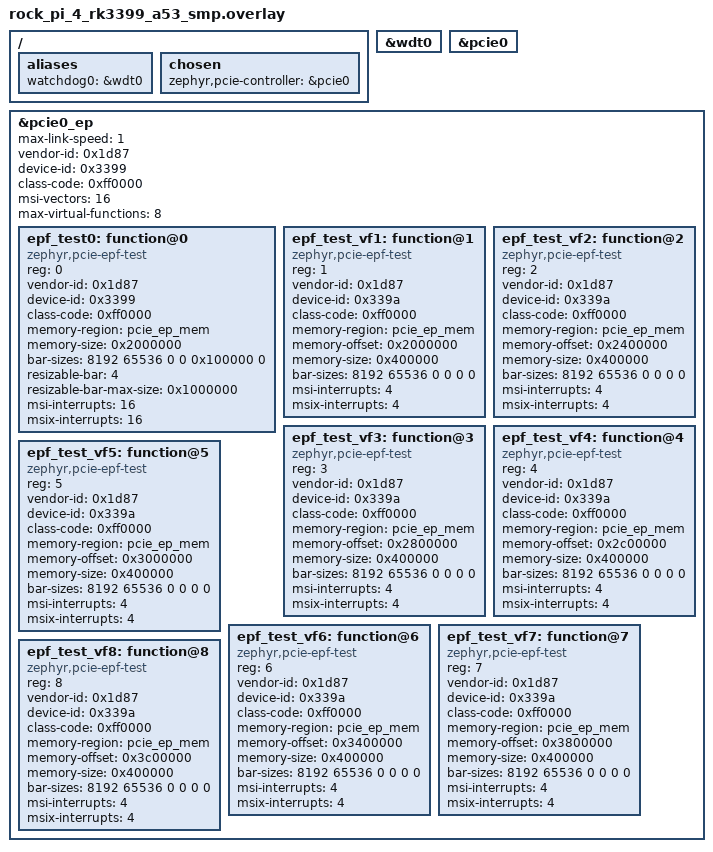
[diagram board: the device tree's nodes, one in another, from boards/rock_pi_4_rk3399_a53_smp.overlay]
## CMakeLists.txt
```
# SPDX-License-Identifier: Apache-2.0

cmake_minimum_required(VERSION 3.20.0)
find_package(Zephyr REQUIRED HINTS $ENV{ZEPHYR_BASE})
project(rk3399_pcie_shell)
target_sources_ifdef(CONFIG_SMP app PRIVATE src/ep_affinity.c)

target_sources(app PRIVATE src/main.c src/cpuinfo.c)
```

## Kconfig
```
# Copyright The Zephyr Project Contributors
# SPDX-License-Identifier: Apache-2.0

source "Kconfig.zephyr"

if SSH_SERVER

config PCIE_SHELL_SSH_USERNAME
	string "SSH user name (empty: any)"
	default "root"

config PCIE_SHELL_SSH_PASSWORD
	string "SSH password"
	default ""
	help
	  Stored in clear text in the image. Empty: the server is not
	  started.

config PCIE_SHELL_SSH_HOST_KEY_BITS
	int "RSA host key size"
	default 2048
	help
	  Generated on the first boot and kept in the settings file on the
	  eMMC FAT; without it, a new key (and fingerprint) on every boot.

endif
```

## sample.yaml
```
sample:
  name: RK3399 PCIe shell (root complex / endpoint)
tests:
  sample.boards.rockchip.rk3399.pcie_shell:
    platform_allow:
      - rock_pi_4/rk3399/a53
      - rock_pi_4/rk3399/a53/smp
      - rock_pi_4/rk3399/a53/hmp
    tags: pcie
    build_only: true
  sample.boards.rockchip.rk3399.pcie_shell.ssh:
    platform_allow:
      - rock_pi_4/rk3399/a53/smp
      - rock_pi_4/rk3399/a53/hmp
    tags: pcie
    build_only: true
    extra_args:
      - EXTRA_CONF_FILE=ssh.conf
      - CONFIG_PCIE_SHELL_SSH_PASSWORD="test"
```

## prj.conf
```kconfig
CONFIG_GPIO=y
CONFIG_LOG=y
CONFIG_SHELL=y
CONFIG_KERNEL_SHELL=y
CONFIG_DEVMEM_SHELL=y
CONFIG_REBOOT=y
CONFIG_SHELL_STACK_SIZE=8192

# root complex
CONFIG_PCIE=y
CONFIG_PCIE_CONTROLLER=y
# endpoint
CONFIG_PCIE_ENDPOINT=y
CONFIG_PCIE_EP_LOG_LEVEL_INF=y
CONFIG_CRC=y
CONFIG_TEST_RANDOM_GENERATOR=y

# config space 32 MiB + outbound 32 MiB + BAR carveout, mapped at run time
CONFIG_KERNEL_VM_SIZE=0x10000000
CONFIG_MAX_XLAT_TABLES=64

# eMMC: boot medium and storage (FAT from 16 MiB, mounted at /EMMC: before
# the PCIe role is read); the micro SD slot
# is left to the JTAG breakout: host only, no SD card disk
CONFIG_SDHC=y
CONFIG_SDHC_INIT_PRIORITY=70
CONFIG_DISK_ACCESS=y
CONFIG_MMC_STACK=y
CONFIG_DISK_DRIVER_MMC=y
CONFIG_FILE_SYSTEM=y
# FAT registered before the eMMC mount (76): default 99 is too late
CONFIG_FILE_SYSTEM_INIT_PRIORITY=74
# the disk drivers on top of the SDHC hosts too (default 90)
CONFIG_SD_INIT_PRIORITY=72
CONFIG_FAT_FILESYSTEM_ELM=y
CONFIG_FS_FATFS_LFN=y
# a blank eMMC stays blank: mkfs over the whole disk would cover the boot area
CONFIG_FS_FATFS_MOUNT_MKFS=n
CONFIG_FILE_SYSTEM_SHELL=y
CONFIG_SETTINGS=y
CONFIG_SETTINGS_FILE=y
CONFIG_SETTINGS_FILE_PATH="/EMMC:/settings"
CONFIG_PCIE_ROLE_SETTINGS=y
CONFIG_MAIN_STACK_SIZE=8192

# SPI flash (4A+/4B+/4C): not used for booting; an old image there would
# win over the eMMC (BootROM order), "flash erase" clears it
CONFIG_SPI=y
CONFIG_FLASH=y
CONFIG_FLASH_SHELL=y

# I2C0: PMIC and CPU regulators ("i2c scan i2c@ff3c0000")
CONFIG_I2C=y
CONFIG_I2C_SHELL=y

# CPU core supplies for "cpu freq" (RK808 DCDC_REG2, SYR827), "regulator" shell
CONFIG_REGULATOR=y
CONFIG_REGULATOR_SHELL=y

# "fwupdate ymodem" over the shell UART (tio ctrl-t y): <img>-rock_pi_4-spi.bin
# into the SPI NOR boot_partition, or on a board without SPI NOR
# <img>-rock_pi_4-boot.bin into the eMMC boot area
CONFIG_FLASH_MAP=y
CONFIG_FWUPDATE=y
CONFIG_FWUPDATE_BOOT_DISK=y

# SR-IOV strap: the core shows its SR-IOV capability (VFs not driven yet)
CONFIG_PCIE_EPC_RK3399_SRIOV=y

# doorbell: host writes to a BAR on the GIC ITS raise an LPI (epf_test)
CONFIG_GIC_V3_ITS=y

# Ethernet (GMAC + RTL8211E): DHCP, mDNS (rockpi4-<mac>.local), "net" shell
# and "fwupdate tcp" (nc -N <board> 6969 < <img>-rock_pi_4-boot.bin)
CONFIG_NETWORKING=y
CONFIG_ETH_DRIVER=y
CONFIG_NET_L2_ETHERNET_MGMT=y
CONFIG_NET_IPV4=y
CONFIG_NET_IPV6=n
CONFIG_NET_TCP=y
CONFIG_NET_UDP=y
CONFIG_NET_DHCPV4=y
# first DISCOVER 1..2 s after the link, not up to 10 s (RFC 2131 4.4.1)
CONFIG_NET_DHCPV4_INITIAL_DELAY_MAX=2
CONFIG_NET_SOCKETS=y
CONFIG_NET_HOSTNAME_ENABLE=y
CONFIG_NET_HOSTNAME="rockpi4"
CONFIG_NET_HOSTNAME_UNIQUE=y
CONFIG_MDNS_RESPONDER=y
CONFIG_NET_SHELL=y
CONFIG_NET_PKT_RX_COUNT=32
CONFIG_NET_PKT_TX_COUNT=32
CONFIG_NET_BUF_RX_COUNT=64
CONFIG_NET_BUF_TX_COUNT=64
CONFIG_NET_RX_STACK_SIZE=4096
CONFIG_FWUPDATE_TCP=y

# reset when the image hangs (main.c; "wdt off" for debugging with SWD)
CONFIG_WATCHDOG=y
CONFIG_TASK_WDT=y

# PMU counters for the "cpu" command
CONFIG_ARM64_PMUV3=y
```

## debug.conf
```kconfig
# boot debugging: markers between init priorities, logs printed at once
CONFIG_SAMPLE_INIT_TRACE=y
CONFIG_EARLY_CONSOLE=y
CONFIG_LOG_MODE_IMMEDIATE=y
CONFIG_SDHC_LOG_LEVEL_DBG=y
CONFIG_SD_LOG_LEVEL_DBG=y
CONFIG_PCIE_EP_LOG_LEVEL_DBG=y
CONFIG_SPI_LOG_LEVEL_DBG=y
# printk and logs straight to the UART, not through the shell log backend
# (that one only prints once the shell thread runs)
CONFIG_LOG_PRINTK=n
CONFIG_SHELL_LOG_BACKEND=n
CONFIG_LOG_BACKEND_UART=y
```

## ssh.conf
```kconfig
# SSH shell: EXTRA_CONF_FILE=ssh.conf and
# -DCONFIG_PCIE_SHELL_SSH_PASSWORD=\"...\"; ssh root@rockpi4-<mac>.local
CONFIG_SSH_SERVER=y
CONFIG_SSH_SERVER_MAX_CLIENTS=2
CONFIG_SSH_MAX_CHANNELS=2
CONFIG_SSH_MAX_HOST_KEYS=1
CONFIG_MBEDTLS=y
CONFIG_MAIN_STACK_SIZE=16384
# ssh <board> '<command>'
CONFIG_SHELL_SSH_EXEC=y
CONFIG_SHELL_DUMMY_INIT_LOG_LEVEL_NONE=y
CONFIG_SHELL_PROMPT_DUMMY=""
CONFIG_HWINFO_SHELL=y
CONFIG_ZVFS_POLL_MAX=10
CONFIG_ZVFS_OPEN_MAX=16
```

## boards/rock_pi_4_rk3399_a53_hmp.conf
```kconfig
# The endpoint gets CPU1: the test function's command work queue is pinned
# there and an SMP level init routes the endpoint interrupts to it; the
# doorbell LPIs follow the work queue.
CONFIG_SCHED_CPU_MASK=y
CONFIG_PCIE_EPF_TEST_CPU=1

# Scheduler IPIs only to the CPUs that can run the woken thread: without
# this every wakeup of the pinned work queue interrupts all six CPUs.
CONFIG_IPI_OPTIMIZE=y
CONFIG_IPI_OPTIMIZE_IDLE=y
```

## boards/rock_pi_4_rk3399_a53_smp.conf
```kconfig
# The endpoint gets CPU1: the test function's command work queue is pinned
# there and an SMP level init routes the endpoint interrupts to it; the
# doorbell LPIs follow the work queue.
CONFIG_SCHED_CPU_MASK=y
CONFIG_PCIE_EPF_TEST_CPU=1

# Scheduler IPIs only to the CPUs that can run the woken thread: without
# this every wakeup of the pinned work queue interrupts all four CPUs.
CONFIG_IPI_OPTIMIZE=y
CONFIG_IPI_OPTIMIZE_IDLE=y
```

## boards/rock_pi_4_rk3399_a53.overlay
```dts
/*
 * Copyright (c) 2026 Jiri Kastner
 * SPDX-License-Identifier: Apache-2.0
 *
 * Both roles of the one controller; CONFIG_PCIE_ROLE picks at boot.
 */

/ {
	aliases {
		watchdog0 = &wdt0;
	};

	chosen {
		zephyr,pcie-controller = &pcie0;
	};
};

/* resets the board when the image hangs (task watchdog in main.c) */
&wdt0 {
	status = "okay";
};

&pcie0 {
	status = "okay";
};

&pcie0_ep {
	/* Gen2 over the crossover cable drops the data link every few hundred
	 * ms, and every drop resets the configuration space (BARs, VFs) */
	max-link-speed = <1>;
	vendor-id = <0x1d87>;
	device-id = <0x3399>;
	class-code = <0xff0000>;
	msi-vectors = <16>;
	status = "okay";

	epf_test0: function@0 {
		compatible = "zephyr,pcie-epf-test";
		reg = <0>;
		vendor-id = <0x1d87>;
		device-id = <0x3399>;
		class-code = <0xff0000>;
		memory-region = <&pcie_ep_mem>;
		memory-size = <0x2000000>;
		/* BAR0 registers, 64-bit BARs need even numbers: 32-bit here */
		bar-sizes = <8192 65536 0 0 0x100000 0>;
		/*
		 * BAR4 (with BAR5, 64-bit prefetchable) resizable 1..16 MiB;
		 * BAR0 and BAR1 then grow to 1 MiB, the doorbell block too
		 */
		resizable-bar = <4>;
		resizable-bar-max-size = <0x1000000>;
		msi-interrupts = <16>;
		/* table and PBA after the register block in BAR0 */
		msix-interrupts = <16>;
	};
};

/*
 * SR-IOV: 4 VFs (routing functions 1..4), each a pcie_epf_test with its own
 * 4 MiB of the carveout. The VF BAR layout is shared, so bar-sizes match;
 * BAR4 is left out so 4 VFs fit a 2 MiB bridge window next to the PF.
 * Host: echo 4 > /sys/bus/pci/devices/<bdf>/sriov_numvfs
 */
&pcie0_ep {
	max-virtual-functions = <4>;

	epf_test_vf1: function@1 {
		compatible = "zephyr,pcie-epf-test";
		reg = <1>;
		vendor-id = <0x1d87>;
		device-id = <0x339a>;
		class-code = <0xff0000>;
		memory-region = <&pcie_ep_mem>;
		memory-offset = <0x2000000>;
		memory-size = <0x400000>;
		bar-sizes = <8192 65536 0 0 0 0>;
		msi-interrupts = <4>;
		msix-interrupts = <4>;
	};

	epf_test_vf2: function@2 {
		compatible = "zephyr,pcie-epf-test";
		reg = <2>;
		vendor-id = <0x1d87>;
		device-id = <0x339a>;
		class-code = <0xff0000>;
		memory-region = <&pcie_ep_mem>;
		memory-offset = <0x2400000>;
		memory-size = <0x400000>;
		bar-sizes = <8192 65536 0 0 0 0>;
		msi-interrupts = <4>;
		msix-interrupts = <4>;
	};

	epf_test_vf3: function@3 {
		compatible = "zephyr,pcie-epf-test";
		reg = <3>;
		vendor-id = <0x1d87>;
		device-id = <0x339a>;
		class-code = <0xff0000>;
		memory-region = <&pcie_ep_mem>;
		memory-offset = <0x2800000>;
		memory-size = <0x400000>;
		bar-sizes = <8192 65536 0 0 0 0>;
		msi-interrupts = <4>;
		msix-interrupts = <4>;
	};

	epf_test_vf4: function@4 {
		compatible = "zephyr,pcie-epf-test";
		reg = <4>;
		vendor-id = <0x1d87>;
		device-id = <0x339a>;
		class-code = <0xff0000>;
		memory-region = <&pcie_ep_mem>;
		memory-offset = <0x2c00000>;
		memory-size = <0x400000>;
		bar-sizes = <8192 65536 0 0 0 0>;
		msi-interrupts = <4>;
		msix-interrupts = <4>;
	};
};
```

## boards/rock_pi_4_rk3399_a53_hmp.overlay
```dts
/*
 * Copyright The Zephyr Project Contributors
 * SPDX-License-Identifier: Apache-2.0
 */

#include "rock_pi_4_rk3399_a53_smp.overlay"
```

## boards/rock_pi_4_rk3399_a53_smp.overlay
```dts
/*
 * Copyright (c) 2026 Jiri Kastner
 * SPDX-License-Identifier: Apache-2.0
 *
 * Both roles of the one controller; CONFIG_PCIE_ROLE picks at boot.
 */

/ {
	aliases {
		watchdog0 = &wdt0;
	};

	chosen {
		zephyr,pcie-controller = &pcie0;
	};
};

/* resets the board when the image hangs (task watchdog in main.c) */
&wdt0 {
	status = "okay";
};

&pcie0 {
	status = "okay";
};

&pcie0_ep {
	/* Gen2 over the crossover cable drops the data link every few hundred
	 * ms, and every drop resets the configuration space (BARs, VFs) */
	max-link-speed = <1>;
	vendor-id = <0x1d87>;
	device-id = <0x3399>;
	class-code = <0xff0000>;
	msi-vectors = <16>;
	status = "okay";

	epf_test0: function@0 {
		compatible = "zephyr,pcie-epf-test";
		reg = <0>;
		vendor-id = <0x1d87>;
		device-id = <0x3399>;
		class-code = <0xff0000>;
		memory-region = <&pcie_ep_mem>;
		memory-size = <0x2000000>;
		/* BAR0 registers, 64-bit BARs need even numbers: 32-bit here */
		bar-sizes = <8192 65536 0 0 0x100000 0>;
		/*
		 * BAR4 (with BAR5, 64-bit prefetchable) resizable 1..16 MiB;
		 * BAR0 and BAR1 then grow to 1 MiB, the doorbell block too
		 */
		resizable-bar = <4>;
		resizable-bar-max-size = <0x1000000>;
		msi-interrupts = <16>;
		/* table and PBA after the register block in BAR0 */
		msix-interrupts = <16>;
	};
};

/*
 * SR-IOV: 8 VFs (routing functions 1..8, the most the core has), each a
 * pcie_epf_test with its own 4 MiB of the carveout after the PF's 32 MiB.
 * The VF BAR layout is shared, so bar-sizes match; BAR4 is left out, so all
 * 8 VFs take 576 KiB of non-prefetchable window next to the PF's 2 MiB.
 * VF 8 has routing ID 8, device 1 without ARI: the host reaches it only if
 * the downstream port above forwards ARI (DevCap2 ARIFwd+); otherwise 7 VFs.
 * Host: pcictl sriov <bdf> 8 (or echo 8 > /sys/bus/pci/devices/<bdf>/sriov_numvfs)
 */
&pcie0_ep {
	max-virtual-functions = <8>;

	epf_test_vf1: function@1 {
		compatible = "zephyr,pcie-epf-test";
		reg = <1>;
		vendor-id = <0x1d87>;
		device-id = <0x339a>;
		class-code = <0xff0000>;
		memory-region = <&pcie_ep_mem>;
		memory-offset = <0x2000000>;
		memory-size = <0x400000>;
		bar-sizes = <8192 65536 0 0 0 0>;
		msi-interrupts = <4>;
		msix-interrupts = <4>;
	};

	epf_test_vf2: function@2 {
		compatible = "zephyr,pcie-epf-test";
		reg = <2>;
		vendor-id = <0x1d87>;
		device-id = <0x339a>;
		class-code = <0xff0000>;
		memory-region = <&pcie_ep_mem>;
		memory-offset = <0x2400000>;
		memory-size = <0x400000>;
		bar-sizes = <8192 65536 0 0 0 0>;
		msi-interrupts = <4>;
		msix-interrupts = <4>;
	};

	epf_test_vf3: function@3 {
		compatible = "zephyr,pcie-epf-test";
		reg = <3>;
		vendor-id = <0x1d87>;
		device-id = <0x339a>;
		class-code = <0xff0000>;
		memory-region = <&pcie_ep_mem>;
		memory-offset = <0x2800000>;
		memory-size = <0x400000>;
		bar-sizes = <8192 65536 0 0 0 0>;
		msi-interrupts = <4>;
		msix-interrupts = <4>;
	};

	epf_test_vf4: function@4 {
		compatible = "zephyr,pcie-epf-test";
		reg = <4>;
		vendor-id = <0x1d87>;
		device-id = <0x339a>;
		class-code = <0xff0000>;
		memory-region = <&pcie_ep_mem>;
		memory-offset = <0x2c00000>;
		memory-size = <0x400000>;
		bar-sizes = <8192 65536 0 0 0 0>;
		msi-interrupts = <4>;
		msix-interrupts = <4>;
	};

	epf_test_vf5: function@5 {
		compatible = "zephyr,pcie-epf-test";
		reg = <5>;
		vendor-id = <0x1d87>;
		device-id = <0x339a>;
		class-code = <0xff0000>;
		memory-region = <&pcie_ep_mem>;
		memory-offset = <0x3000000>;
		memory-size = <0x400000>;
		bar-sizes = <8192 65536 0 0 0 0>;
		msi-interrupts = <4>;
		msix-interrupts = <4>;
	};

	epf_test_vf6: function@6 {
		compatible = "zephyr,pcie-epf-test";
		reg = <6>;
		vendor-id = <0x1d87>;
		device-id = <0x339a>;
		class-code = <0xff0000>;
		memory-region = <&pcie_ep_mem>;
		memory-offset = <0x3400000>;
		memory-size = <0x400000>;
		bar-sizes = <8192 65536 0 0 0 0>;
		msi-interrupts = <4>;
		msix-interrupts = <4>;
	};

	epf_test_vf7: function@7 {
		compatible = "zephyr,pcie-epf-test";
		reg = <7>;
		vendor-id = <0x1d87>;
		device-id = <0x339a>;
		class-code = <0xff0000>;
		memory-region = <&pcie_ep_mem>;
		memory-offset = <0x3800000>;
		memory-size = <0x400000>;
		bar-sizes = <8192 65536 0 0 0 0>;
		msi-interrupts = <4>;
		msix-interrupts = <4>;
	};

	epf_test_vf8: function@8 {
		compatible = "zephyr,pcie-epf-test";
		reg = <8>;
		vendor-id = <0x1d87>;
		device-id = <0x339a>;
		class-code = <0xff0000>;
		memory-region = <&pcie_ep_mem>;
		memory-offset = <0x3c00000>;
		memory-size = <0x400000>;
		bar-sizes = <8192 65536 0 0 0 0>;
		msi-interrupts = <4>;
		msix-interrupts = <4>;
	};
};
```

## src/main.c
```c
/*
 * Copyright (c) 2026 Jiri Kastner
 * SPDX-License-Identifier: Apache-2.0
 *
 * RK3399 PCIe in either role, driven from the shell ("pcie ..."). The eMMC
 * is the boot medium and the storage: its FAT partition is mounted at
 * /EMMC: before the PCIe role is read from settings. The micro SD slot is
 * left to the JTAG breakout (no SD card disk); "emmc update <file>" rewrites
 * the eMMC boot area (MBR, idbloader, FIT) from a file, e.g. on /EMMC:.
 * The BootROM tries the SPI NOR first: "fwupdate ymodem" writes
 * <img>-rock_pi_4-spi.bin there over the shell UART, "flash erase" of its
 * first sector falls back to the eMMC.
 * With ssh.conf, an SSH server with the shell backend starts after DHCP;
 * its RSA host key is kept in settings.
 */

#include <stdlib.h>
#include <string.h>

#include <ff.h>
#include <zephyr/device.h>
#include <zephyr/drivers/pcie/role.h>
#include <zephyr/fs/fs.h>
#include <zephyr/init.h>
#include <zephyr/kernel.h>
#include <zephyr/net/net_if.h>
#include <zephyr/net/dhcpv4.h>
#if defined(CONFIG_SSH_SERVER)
#include <stdio.h>
#include <zephyr/net/ssh/server.h>
#include <zephyr/shell/shell_uart.h>
#endif
#include <zephyr/shell/shell.h>
#include <zephyr/storage/disk_access.h>
#include <zephyr/sys/printk.h>
#include <zephyr/sys/sys_io.h>

static FATFS fat_emmc;
static struct fs_mount_t emmc_mnt = {
	.type = FS_FATFS,
	.mnt_point = "/EMMC:",
	.fs_data = &fat_emmc,
	/* no mkfs on a blank eMMC: it would cover the boot area at sector 64 */
	.flags = FS_MOUNT_FLAG_NO_FORMAT,
};
static int emmc_mount_ret = -ENODEV;

/* after the SDHC hosts (70), the disks (72) and FAT (74); before the PCIe role (81) */
static int emmc_mount(void)
{
	emmc_mount_ret = fs_mount(&emmc_mnt);
	return 0;
}
SYS_INIT(emmc_mount, POST_KERNEL, 76);

#define SECT    512U
#define CHUNK   (64U * SECT)
static uint8_t buf[CHUNK] __aligned(64);
static uint8_t chk[CHUNK] __aligned(64);

/*
 * Boot area of a raw image (MBR, idbloader at 64, FIT at 2048) from a file
 * to the eMMC from sector 0. The FAT from BOOT_AREA on, where the file may
 * live, is left alone: a full -emmc.bin is cut there.
 */
#define BOOT_AREA (32768U * SECT)
static int cmd_update(const struct shell *sh, size_t argc, char **argv)
{
	struct fs_dirent st;
	struct fs_file_t f;
	uint32_t count = 0, sz = 0;
	size_t done = 0;
	int ret;

	ret = fs_stat(argv[1], &st);
	if (ret != 0) {
		shell_error(sh, "%s: %d", argv[1], ret);
		return ret;
	}
	if (st.size > BOOT_AREA) {
		st.size = BOOT_AREA;
	}
	ret = disk_access_init("EMMC");
	if (ret == 0) {
		ret = disk_access_ioctl("EMMC", DISK_IOCTL_GET_SECTOR_COUNT, &count);
	}
	if (ret == 0) {
		ret = disk_access_ioctl("EMMC", DISK_IOCTL_GET_SECTOR_SIZE, &sz);
	}
	if (ret != 0 || sz != SECT) {
		shell_error(sh, "eMMC not usable (%d, sector %u)", ret, sz);
		return ret ? ret : -EIO;
	}
	if (DIV_ROUND_UP(st.size, SECT) > count) {
		shell_error(sh, "image %zu B > eMMC %u sectors", st.size, count);
		return -EFBIG;
	}
	fs_file_t_init(&f);
	ret = fs_open(&f, argv[1], FS_O_READ);
	if (ret != 0) {
		return ret;
	}
	shell_print(sh, "%s: %zu bytes to the eMMC (%u sectors)", argv[1], st.size, count);
	while (done < st.size) {
		ssize_t n = fs_read(&f, buf, MIN(CHUNK, st.size - done));
		uint32_t sect, ns;

		if (n <= 0) {
			ret = n < 0 ? (int)n : -EIO;
			break;
		}
		memset(buf + n, 0, CHUNK - n);
		sect = done / SECT;
		ns = DIV_ROUND_UP(n, SECT);
		ret = disk_access_write("EMMC", buf, sect, ns);
		if (ret == 0) {
			ret = disk_access_read("EMMC", chk, sect, ns);
		}
		if (ret == 0 && memcmp(buf, chk, ns * SECT) != 0) {
			shell_error(sh, "verify failed at sector %u", sect);
			ret = -EIO;
		}
		if (ret != 0) {
			break;
		}
		done += n;
		if ((done % MB(1)) == 0) {
			shell_fprintf(sh, SHELL_NORMAL, ".");
		}
	}
	fs_close(&f);
	(void)disk_access_ioctl("EMMC", DISK_IOCTL_CTRL_SYNC, NULL);
	shell_print(sh, "\n%s: %zu bytes written and verified%s", ret ? "FAILED" : "done", done,
		    ret ? "" : "; reset to boot it");
	return ret;
}

SHELL_STATIC_SUBCMD_SET_CREATE(sub_emmc,
	SHELL_CMD_ARG(update, NULL,
		      "<file>: write the boot area (first 16 MiB) of a raw image to the "
		      "eMMC and verify (e.g. /EMMC:/154-rock_pi_4-boot.bin)",
		      cmd_update, 2, 0),
	SHELL_SUBCMD_SET_END);
SHELL_CMD_REGISTER(emmc, &sub_emmc, "eMMC install", NULL);

/*
 * The BAR carveout (pcie_ep_mem) is identity mapped by its DT memory
 * attribute, so devmem, which maps again, panics on it: read and write it
 * here through that mapping. Offsets: PF at 0, VF n at n * 4 MiB.
 */
#define EP_MEM_BASE DT_REG_ADDR(DT_NODELABEL(pcie_ep_mem))
#define EP_MEM_SIZE DT_REG_SIZE(DT_NODELABEL(pcie_ep_mem))

static int cmd_epmem(const struct shell *sh, size_t argc, char **argv)
{
	unsigned long off = strtoul(argv[1], NULL, 0);
	unsigned long n = argc > 2 ? strtoul(argv[2], NULL, 0) : 4;

	if (off >= EP_MEM_SIZE || (off & 3U) != 0U) {
		shell_error(sh, "offset 0x%lx: word aligned, below 0x%lx", off,
			    (unsigned long)EP_MEM_SIZE);
		return -EINVAL;
	}
	if (argc > 3) {
		sys_write32((uint32_t)strtoul(argv[3], NULL, 0), EP_MEM_BASE + off);
	}
	for (unsigned long i = 0; i < n && off + i * 4U < EP_MEM_SIZE; i++) {
		if ((i % 4U) == 0U) {
			shell_fprintf(sh, SHELL_NORMAL, "%s%08lx:", i ? "\n" : "", off + i * 4U);
		}
		shell_fprintf(sh, SHELL_NORMAL, " %08x", sys_read32(EP_MEM_BASE + off + i * 4U));
	}
	shell_print(sh, "");
	return 0;
}
#ifdef CONFIG_RK3399_NOC_ERRLOG
#include <rk3399_noc.h>
#include <zephyr/fatal.h>
#include <zephyr/logging/log_ctrl.h>

/* show what the interconnect logged (SErrors through the PCIe window) */
void k_sys_fatal_error_handler(unsigned int reason, const struct arch_esf *esf)
{
	ARG_UNUSED(esf);
	LOG_PANIC();
	rk3399_noc_errlog_dump();
	printk("Halting system (reason %u)\n", reason);
	(void)arch_irq_lock();
	for (;;) {
	}
}
#endif

SHELL_CMD_ARG_REGISTER(epmem, NULL,
		       "<offset> [words] [value]: BAR carveout (PF 0, VF n at n*4M); value writes "
		       "the first word",
		       cmd_epmem, 2, 2);

/*
 * Watchdog: a hang (SError halt, deadlock, stuck system work queue) resets
 * the board after WDT_TIMEOUT_MS instead of waiting for a power cycle. The
 * system work queue feeds a task watchdog channel; the task watchdog feeds
 * the hardware one, so a dead kernel stops both. A running DesignWare
 * watchdog cannot be stopped: "wdt off" keeps it off from the next boot,
 * for looking at a hung board over SWD.
 */
#if DT_HAS_ALIAS(watchdog0) && defined(CONFIG_TASK_WDT)
#include <zephyr/settings/settings.h>
#include <zephyr/sys/device_mmio.h>
#include <zephyr/task_wdt/task_wdt.h>

#define WDT_TIMEOUT_MS 10000U
#define CRU_BASE       0xff760000UL
#define CRU_GLB_RST_ST 0x514U

static bool wdt_disabled;
static int wdt_channel = -1;

static void wdt_feed(struct k_work *work)
{
	(void)task_wdt_feed(wdt_channel);
	(void)k_work_reschedule(k_work_delayable_from_work(work), K_SECONDS(1));
}

static K_WORK_DELAYABLE_DEFINE(wdt_work, wdt_feed);

static int wdt_settings_set(const char *key, size_t len, settings_read_cb read_cb, void *cb_arg)
{
	uint8_t v;

	if (strcmp(key, "wdt") != 0 || len != 1U) {
		return -ENOENT;
	}
	if (read_cb(cb_arg, &v, 1) == 1) {
		wdt_disabled = v == 0U;
	}
	return 0;
}

SETTINGS_STATIC_HANDLER_DEFINE(pshell, "pshell", NULL, wdt_settings_set, NULL, NULL);

/* why the last reset happened (CRU_GLB_RST_ST, sticky until the next one) */
static void reset_reason(void)
{
	static const char *const why[] = {"first global", "second global", "tsadc first",
					  "tsadc second", "watchdog first", "watchdog second"};
	mm_reg_t cru;
	uint32_t st;

	device_map(&cru, CRU_BASE, 0x1000, K_MEM_CACHE_NONE);
	st = sys_read32(cru + CRU_GLB_RST_ST);
	printk("reset: 0x%02x", st);
	for (unsigned int i = 0; i < ARRAY_SIZE(why); i++) {
		if ((st & BIT(i)) != 0U) {
			printk(" %s", why[i]);
		}
	}
	printk("%s\n", st == 0U ? " power-on" : "");
}

static void wdt_start(void)
{
	const struct device *hw = DEVICE_DT_GET(DT_ALIAS(watchdog0));
	int ret;

	reset_reason();
	(void)settings_load_subtree("pshell");
	if (wdt_disabled) {
		printk("watchdog off (\"wdt on\" for the next boot)\n");
		return;
	}
	ret = task_wdt_init(device_is_ready(hw) ? hw : NULL);
	if (ret == 0) {
		wdt_channel = task_wdt_add(WDT_TIMEOUT_MS, NULL, NULL);
	}
	if (ret != 0 || wdt_channel < 0) {
		printk("watchdog: %d %d\n", ret, wdt_channel);
		return;
	}
	(void)k_work_schedule(&wdt_work, K_NO_WAIT);
	printk("watchdog: reset after %u ms without the system work queue%s\n", WDT_TIMEOUT_MS,
	       device_is_ready(hw) ? "" : " (no hardware watchdog: a dead kernel is not caught)");
}

static int cmd_wdt(const struct shell *sh, size_t argc, char **argv)
{
	uint8_t on;
	int ret;

	if (argc < 2) {
		shell_print(sh, "watchdog %s, saved for the next boot: %s",
			    wdt_channel >= 0 ? "running" : "off", wdt_disabled ? "off" : "on");
		return 0;
	}
	if (strcmp(argv[1], "on") != 0 && strcmp(argv[1], "off") != 0) {
		shell_error(sh, "on | off");
		return -EINVAL;
	}
	on = strcmp(argv[1], "on") == 0;
	ret = settings_save_one("pshell/wdt", &on, 1);
	if (ret == 0) {
		wdt_disabled = !on;
	}
	shell_print(sh, "watchdog %s from the next boot%s (%d)", argv[1],
		    (!on && wdt_channel >= 0) ? "; the running one cannot be stopped" : "", ret);
	return ret;
}

SHELL_CMD_ARG_REGISTER(wdt, NULL, "[on|off] Watchdog: state, or on/off from the next boot",
		       cmd_wdt, 1, 1);
#else
static void wdt_start(void)
{
}
#endif

#if defined(CONFIG_SSH_SERVER)
static int run(const char *cmd)
{
	int ret = shell_execute_cmd(shell_backend_uart_get_ptr(), cmd);

	if (ret != 0) {
		printk("ssh: \"%s\": %d\n", cmd, ret);
	}
	return ret;
}

/* host key 0 from settings, or a new one saved there */
static void ssh_start(void)
{
	char cmd[96];

	if (CONFIG_PCIE_SHELL_SSH_PASSWORD[0] == '\0') {
		printk("ssh: no password configured, server not started\n");
		return;
	}
	while (!shell_ready(shell_backend_uart_get_ptr())) {
		k_msleep(10);
	}
	if (run("net ssh_key load 0 priv id_rsa") != 0) {
		printk("ssh: generating a %d bit RSA host key\n",
		       CONFIG_PCIE_SHELL_SSH_HOST_KEY_BITS);
		snprintf(cmd, sizeof(cmd), "net ssh_key gen 0 rsa %d",
			 CONFIG_PCIE_SHELL_SSH_HOST_KEY_BITS);
		if (run(cmd) != 0) {
			return;
		}
		(void)run("net ssh_key save 0 priv id_rsa");
	}
	ssh_server_set_banner_text("Board " CONFIG_BOARD_TARGET);
	snprintf(cmd, sizeof(cmd), "net sshd start -i 0 -k 0%s%s -p %s",
		 CONFIG_PCIE_SHELL_SSH_USERNAME[0] != '\0' ? " -u " : "",
		 CONFIG_PCIE_SHELL_SSH_USERNAME, CONFIG_PCIE_SHELL_SSH_PASSWORD);
	if (run(cmd) == 0) {
		printk("ssh: listening on port %d\n", CONFIG_SSH_PORT);
	}
}
#endif

int main(void)
{
	enum pcie_role saved;
	bool have = pcie_role_saved(&saved);

	wdt_start();
	printk("eMMC: %s (%d)\n", emmc_mount_ret == 0 ? "mounted at /EMMC:" : "no FAT",
	       emmc_mount_ret);
	printk("RK3399 PCIe %s (saved: %s, in %s); \"pcie controller mode rc|ep\", "
	       "then a warm reset (\"kernel reboot warm\")\n",
	       pcie_role_get() == PCIE_ROLE_RC ? "root complex" : "endpoint",
	       have ? (saved == PCIE_ROLE_RC ? "rc" : "ep") : "-", pcie_role_storage());

	/* the client waits for the carrier itself and restarts on link changes */
	if (IS_ENABLED(CONFIG_NET_DHCPV4) && net_if_get_default() != NULL) {
		net_dhcpv4_start(net_if_get_default());
	}
#if defined(CONFIG_SSH_SERVER)
	ssh_start();
#endif
	return 0;
}
```

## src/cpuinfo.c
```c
/*
 * SPDX-FileCopyrightText: Copyright The Zephyr Project Contributors
 * SPDX-License-Identifier: Apache-2.0
 *
 * "cpu": system registers, memory attributes of a few addresses and a
 * core clock / memory bandwidth estimate, to tell a slow clock from
 * memory that is not cached. With the PMU each benchmark also shows
 * core cycles, instructions, cache refills and exceptions taken.
 *
 * The PMU, the cache and the GIC CPU interface are per CPU: with SMP every
 * measurement runs in a thread pinned to one CPU, so the shell thread
 * moving between CPUs does not mix two of them.
 *
 * "cpu freq": core clocks of both clusters at the operating points of the
 * Linux rk3399.dtsi, with the core supply (devicetree labels vdd_cpu_l and
 * vdd_cpu_b) set to the voltage of the point. "cpu freq save" keeps the
 * current points in settings; they are applied at boot, before the other
 * CPUs start, except after a watchdog reset.
 */

#include <stdlib.h>
#include <string.h>

#include <zephyr/arch/pmu.h>
#include <zephyr/device.h>
#include <zephyr/devicetree.h>
#include <zephyr/drivers/clock_control.h>
#include <zephyr/drivers/regulator.h>
#include <zephyr/dt-bindings/clock/rk3399-cru.h>
#include <zephyr/init.h>
#include <zephyr/kernel.h>
#include <zephyr/settings/settings.h>
#include <zephyr/shell/shell.h>
#include <zephyr/sys/device_mmio.h>
#include <zephyr/sys/printk.h>
#include <zephyr/sys/sys_io.h>
#include <zephyr/sys/util.h>

#define SYSREG(name)                                                                               \
	({                                                                                         \
		uint64_t v_;                                                                       \
		__asm__ volatile("mrs %0, " #name : "=r"(v_));                                     \
		v_;                                                                                \
	})

#define BENCH_BUF KB(256)

static uint8_t bench_buf[BENCH_BUF] __aligned(64);

static const struct {
	pmu_evt_t evt;
	const char *name;
} pmu_evts[] = {
	{PMU_EVT_INST_RETIRED, "insn"},     {PMU_EVT_L1I_CACHE_REFILL, "l1i-refill"},
	{PMU_EVT_L1D_CACHE_REFILL, "l1d-refill"}, {PMU_EVT_L2D_CACHE_REFILL, "l2-refill"},
	{PMU_EVT_EXC_TAKEN, "exc"},         {PMU_EVT_BUS_ACCESS, "bus"},
};

static bool pmu_ok;
static uint32_t pmu_n;

static void pmu_begin(void)
{
	if (!pmu_ok) {
		return;
	}
	pmu_stop();
	pmu_counter_reset_all();
	pmu_cycle_reset();
	pmu_start();
}

static void pmu_end(const struct shell *sh, uint64_t ns)
{
	uint64_t cyc, v[ARRAY_SIZE(pmu_evts)] = {0};

	if (!pmu_ok) {
		return;
	}
	pmu_stop();
	cyc = pmu_cycle_count();
	for (uint32_t i = 0; i < pmu_n; i++) {
		v[i] = pmu_counter_read(i);
	}
	/* insn per cycle, in hundredths */
	uint64_t ipc = (cyc != 0U && pmu_n > 0U) ? v[0] * 100U / cyc : 0U;

	shell_fprintf(sh, SHELL_NORMAL, "      cycles %llu (%llu MHz), IPC %llu.%02llu", cyc,
		      ns ? cyc * 1000U / ns : 0, ipc / 100U, ipc % 100U);
	for (uint32_t i = 0; i < pmu_n; i++) {
		shell_fprintf(sh, SHELL_NORMAL, ", %s %llu", pmu_evts[i].name, v[i]);
	}
	shell_fprintf(sh, SHELL_NORMAL, "\n");
}

static void pmu_setup(const struct shell *sh)
{
	if (pmu_init() != 0) {
		shell_print(sh, "PMU: not usable at this exception level");
		return;
	}
	pmu_n = MIN(pmu_num_counters(), (uint32_t)ARRAY_SIZE(pmu_evts));
	for (uint32_t i = 0; i < pmu_n; i++) {
		(void)pmu_counter_config(i, pmu_evts[i].evt);
	}
	pmu_counter_enable_all();
	pmu_ok = true;
	shell_print(sh, "PMU: %u counters, core clock at PMU init %u MHz (cycles vs. CNTVCT)",
		    pmu_num_counters(), arch_pmu_cpu_freq_mhz());
}

/* stage 1 EL1 translation of va: PAR_EL1 (F, PA, ATTR) */
static uint64_t at_s1e1r(const void *va)
{
	uint64_t par;
	unsigned int key = irq_lock();

	__asm__ volatile("at s1e1r, %1\n\tisb\n\tmrs %0, par_el1" : "=r"(par) : "r"(va));
	irq_unlock(key);
	return par;
}

static void show_at(const struct shell *sh, const char *what, const void *va, uint64_t mair)
{
	uint64_t par = at_s1e1r(va);

	if ((par & 1U) != 0U) {
		shell_print(sh, "%-10s %p: fault, PAR %016llx", what, va, (unsigned long long)par);
		return;
	}
	uint8_t attr = (uint8_t)(par >> 56);
	uint32_t idx;

	for (idx = 0; idx < 8; idx++) {
		if ((uint8_t)(mair >> (8 * idx)) == attr) {
			break;
		}
	}
	shell_print(sh, "%-10s %p -> PA %llx, attr %02x (%s%s), sh %llu, ns %llu", what, va,
		    (unsigned long long)(par & GENMASK64(47, 12)), attr,
		    attr == 0xffU ? "normal WB RW-alloc" : (attr & 0xf0U) == 0U ? "device" :
		    attr == 0x44U ? "normal non-cacheable" : "other",
		    idx < 8 ? "" : ", not in MAIR", (unsigned long long)((par >> 7) & 3U),
		    (unsigned long long)((par >> 9) & 1U));
}

/* 8 dependent adds per iteration: >= 8 core cycles each */
static uint64_t bench_core(uint64_t iters)
{
	uint64_t acc = 0, n = iters, t0, t1;

	t0 = k_cycle_get_64();
	__asm__ volatile("1:\n\t"
			 "add %0, %0, #1\n\tadd %0, %0, #1\n\tadd %0, %0, #1\n\tadd %0, %0, #1\n\t"
			 "add %0, %0, #1\n\tadd %0, %0, #1\n\tadd %0, %0, #1\n\tadd %0, %0, #1\n\t"
			 "subs %1, %1, #1\n\tb.ne 1b"
			 : "+r"(acc), "+r"(n));
	t1 = k_cycle_get_64();
	return k_cyc_to_ns_floor64(t1 - t0);
}

static uint64_t bench_mem(bool write, unsigned int loops)
{
	volatile uint64_t *p = (volatile uint64_t *)bench_buf;
	uint64_t sum = 0, t0, t1;

	t0 = k_cycle_get_64();
	for (unsigned int l = 0; l < loops; l++) {
		for (size_t i = 0; i < BENCH_BUF / 8U; i++) {
			if (write) {
				p[i] = i;
			} else {
				sum += p[i];
			}
		}
	}
	t1 = k_cycle_get_64();
	(void)sum;
	return k_cyc_to_ns_floor64(t1 - t0);
}

static int cpu_info(const struct shell *sh, uint32_t arg)
{
	const uint64_t iters = 10000000ULL;
	uint64_t mair = SYSREG(mair_el1);
	uint64_t sctlr = SYSREG(sctlr_el1);
	uint64_t ns, ns_locked;
	unsigned int key;

	ARG_UNUSED(arg);

	shell_print(sh, "MIDR %08llx MPIDR %08llx CurrentEL %llu CNTFRQ %llu", SYSREG(midr_el1),
		    SYSREG(mpidr_el1), (SYSREG(CurrentEL) >> 2) & 3U, SYSREG(cntfrq_el0));
	shell_print(sh, "SCTLR_EL1 %08llx: M %llu C %llu I %llu", sctlr, sctlr & 1U,
		    (sctlr >> 2) & 1U, (sctlr >> 12) & 1U);
	shell_print(sh, "MAIR_EL1 %016llx TCR_EL1 %016llx", mair, SYSREG(tcr_el1));
	shell_print(sh, "CTR_EL0 %08llx CLIDR_EL1 %08llx", SYSREG(ctr_el0), SYSREG(clidr_el1));
	show_at(sh, "text", (const void *)cpu_info, mair);
	show_at(sh, "bss", bench_buf, mair);
	show_at(sh, "stack", &mair, mair);

	pmu_setup(sh);

	pmu_begin();
	ns = bench_core(iters);
	shell_print(sh, "core: %llu dependent adds in %llu us -> >= %llu MHz", 8ULL * iters,
		    ns / 1000U, ns ? 8000ULL * iters / ns : 0);
	pmu_end(sh, ns);
	key = irq_lock();
	pmu_begin();
	ns_locked = bench_core(iters);
	pmu_stop();
	irq_unlock(key);
	shell_print(sh, "core, irqs locked: %llu us -> >= %llu MHz", ns_locked / 1000U,
		    ns_locked ? 8000ULL * iters / ns_locked : 0);
	pmu_end(sh, ns_locked);

	memset(bench_buf, 0x5a, sizeof(bench_buf)); /* outside the counted period */
	pmu_begin();
	ns = bench_mem(false, 16);
	shell_print(sh, "read  %u KiB x16: %llu us, %llu MB/s", (unsigned int)(BENCH_BUF / 1024U),
		    ns / 1000U, ns ? 16ULL * BENCH_BUF * 1000U / ns : 0);
	pmu_end(sh, ns);
	memset(bench_buf, 0x5a, sizeof(bench_buf)); /* outside the counted period */
	pmu_begin();
	ns = bench_mem(true, 16);
	shell_print(sh, "write %u KiB x16: %llu us, %llu MB/s", (unsigned int)(BENCH_BUF / 1024U),
		    ns / 1000U, ns ? 16ULL * BENCH_BUF * 1000U / ns : 0);
	pmu_end(sh, ns);
	return 0;
}

/*
 * Which interrupt keeps the core busy: with IRQs masked at the core,
 * ICC_HPPIR1_EL1 names the highest priority pending Group 1 interrupt;
 * the PMU counts exceptions taken over a period with IRQs on.
 */
#define HPPIR_SAMPLES 64U
#define INTID_SPURIOUS 1023U

static int cpu_irq(const struct shell *sh, uint32_t ms)
{
	uint32_t ids[HPPIR_SAMPLES], cnt[HPPIR_SAMPLES] = {0}, nids = 0;

	for (uint32_t i = 0; i < HPPIR_SAMPLES; i++) {
		unsigned int key = irq_lock();
		uint64_t t0 = k_cycle_get_64();
		uint32_t id;

		/* 50..1650 us: long enough for a periodic source to become pending */
		while (k_cycle_get_64() - t0 < k_us_to_cyc_ceil64(50U + 25U * i)) {
		}
		id = (uint32_t)SYSREG(S3_0_C12_C12_2) & 0xffffffU; /* ICC_HPPIR1_EL1 */
		irq_unlock(key);

		uint32_t j;

		for (j = 0; j < nids && ids[j] != id; j++) {
		}
		if (j == nids) {
			ids[nids++] = id;
		}
		cnt[j]++;
	}
	shell_print(sh, "pending with IRQs masked, %u samples:", HPPIR_SAMPLES);
	for (uint32_t j = 0; j < nids; j++) {
		shell_print(sh, "  INTID %4u%s: %u", ids[j],
			    ids[j] == INTID_SPURIOUS ? " (none)"
			    : ids[j] >= 32U ? "" : ids[j] >= 16U ? " (PPI)" : " (SGI)", cnt[j]);
	}

	pmu_setup(sh);
	if (pmu_ok) {
		uint64_t exc;

		pmu_begin();
		k_busy_wait(ms * 1000U);
		pmu_stop();
		exc = pmu_counter_read(4);
		shell_print(sh, "exceptions taken in %u ms: %llu (%llu/s)", ms, exc,
			    exc * 1000U / MAX(ms, 1U));
	}
	return 0;
}

typedef int (*cpu_fn_t)(const struct shell *sh, uint32_t arg);

#if defined(CONFIG_SCHED_CPU_MASK) && (CONFIG_MP_MAX_NUM_CPUS > 1)
static K_THREAD_STACK_DEFINE(cpu_stack, 4096);
static struct k_thread cpu_thread;

struct cpu_job {
	cpu_fn_t fn;
	const struct shell *sh;
	uint32_t arg;
	int ret;
};

static void cpu_job_run(void *p1, void *p2, void *p3)
{
	struct cpu_job *job = p1;

	ARG_UNUSED(p2);
	ARG_UNUSED(p3);

	job->ret = job->fn(job->sh, job->arg);
}

/* the shell thread is not pinned: run fn in a thread that stays on cpu */
static int run_on_cpu(int cpu, cpu_fn_t fn, const struct shell *sh, uint32_t arg)
{
	struct cpu_job job = {.fn = fn, .sh = sh, .arg = arg, .ret = -EIO};

	k_thread_create(&cpu_thread, cpu_stack, K_THREAD_STACK_SIZEOF(cpu_stack), cpu_job_run,
			&job, NULL, NULL, k_thread_priority_get(k_current_get()), 0, K_FOREVER);
	if (k_thread_cpu_pin(&cpu_thread, cpu) != 0) {
		k_thread_abort(&cpu_thread);
		return -EINVAL;
	}
	k_thread_start(&cpu_thread);
	(void)k_thread_join(&cpu_thread, K_FOREVER);
	return job.ret;
}
#else
static int run_on_cpu(int cpu, cpu_fn_t fn, const struct shell *sh, uint32_t arg)
{
	ARG_UNUSED(cpu);
	return fn(sh, arg);
}
#endif

static int parse_cpu(const struct shell *sh, const char *s, int *cpu)
{
	char *end;
	unsigned long v = strtoul(s, &end, 0);

	if (*end != '\0' || v >= arch_num_cpus()) {
		shell_error(sh, "CPU %s: 0..%u", s, arch_num_cpus() - 1U);
		return -EINVAL;
	}
	*cpu = (int)v;
	return 0;
}

static int cmd_cpu(const struct shell *sh, size_t argc, char **argv)
{
	unsigned int key = irq_lock();
	int cpu = (int)arch_curr_cpu()->id;

	irq_unlock(key);
	if (argc > 1 && parse_cpu(sh, argv[1], &cpu) != 0) {
		return -EINVAL;
	}
	if (arch_num_cpus() > 1U) {
		shell_print(sh, "CPU%d:", cpu);
	}
	return run_on_cpu(cpu, cpu_info, sh, 0U);
}

static int cmd_cpu_info(const struct shell *sh, size_t argc, char **argv)
{
	return cmd_cpu(sh, argc, argv);
}

static int cmd_cpu_irq(const struct shell *sh, size_t argc, char **argv)
{
	uint32_t ms = argc > 1 ? strtoul(argv[1], NULL, 0) : 100U;
	int first = 0, last = (int)arch_num_cpus() - 1;

	if (argc > 2) {
		if (parse_cpu(sh, argv[2], &first) != 0) {
			return -EINVAL;
		}
		last = first;
	}
	for (int cpu = first; cpu <= last; cpu++) {
		if (arch_num_cpus() > 1U) {
			shell_print(sh, "CPU%d:", cpu);
		}
		(void)run_on_cpu(cpu, cpu_irq, sh, ms);
	}
	shell_print(sh, "SPI n = INTID - 32 (devicetree GIC_SPI n)");
	return 0;
}

#if DT_NODE_HAS_STATUS_OKAY(DT_NODELABEL(cru_clk))
struct opp {
	uint16_t mhz;
	uint16_t mv;
};

static const struct opp opp_little[] = {
	{408, 825}, {600, 825}, {816, 850}, {1008, 925}, {1200, 1000}, {1416, 1125},
};

static const struct opp opp_big[] = {
	{408, 825},   {600, 825},   {816, 825},   {1008, 875},
	{1200, 950},  {1416, 1025}, {1608, 1100}, {1800, 1200},
};

static const struct cluster {
	const char *name;
	uint32_t clk;
	const struct device *supply;
	const struct opp *opp;
	size_t nopp;
} clusters[] = {
	{"little", ARMCLKL, DEVICE_DT_GET_OR_NULL(DT_NODELABEL(vdd_cpu_l)), opp_little,
	 ARRAY_SIZE(opp_little)},
	{"big", ARMCLKB, DEVICE_DT_GET_OR_NULL(DT_NODELABEL(vdd_cpu_b)), opp_big,
	 ARRAY_SIZE(opp_big)},
};

/* supply voltage in uV, 0 when there is no supply regulator or it can't be read */
static int32_t supply_uv(const struct cluster *c)
{
	int32_t uv;

	if (c->supply == NULL || !device_is_ready(c->supply) ||
	    regulator_get_voltage(c->supply, &uv) != 0) {
		return 0;
	}
	return uv;
}

static void freq_show(const struct shell *sh, const struct device *cru, const struct cluster *c)
{
	uint32_t hz = 0;
	int32_t uv = supply_uv(c);

	(void)clock_control_get_rate(cru, (clock_control_subsys_t)(uintptr_t)c->clk, &hz);
	if (uv == 0) {
		shell_print(sh, "%-6s %4u MHz, supply not readable", c->name, hz / 1000000U);
	} else {
		shell_print(sh, "%-6s %4u MHz, supply %d mV", c->name, hz / 1000000U, uv / 1000);
	}
}

/* errors to the shell, or to the console at boot (sh == NULL) */
#define freq_err(sh, fmt, ...)                                                                     \
	do {                                                                                       \
		if ((sh) != NULL) {                                                                \
			shell_error(sh, fmt, ##__VA_ARGS__);                                       \
		} else {                                                                           \
			printk("cpu freq: " fmt "\n", ##__VA_ARGS__);                              \
		}                                                                                  \
	} while (false)

/*
 * Voltage up before the clock, down after it, so the cluster never runs
 * faster than its supply allows.
 */
static int freq_set(const struct shell *sh, const struct device *cru, const struct cluster *c,
		    const struct opp *o)
{
	int32_t uv = supply_uv(c), want = (int32_t)o->mv * 1000;
	int ret;

	if (uv == 0) {
		freq_err(sh, "%s: supply not ready", c->name);
		return -ENODEV;
	}
	if (want > uv) {
		ret = regulator_set_voltage(c->supply, want, want);
		if (ret != 0) {
			freq_err(sh, "%s: supply %u mV: %d", c->name, o->mv, ret);
			return ret;
		}
	}
	ret = clock_control_set_rate(cru, (clock_control_subsys_t)(uintptr_t)c->clk,
				     (clock_control_subsys_rate_t)(uintptr_t)(o->mhz * 1000000U));
	if (ret != 0) {
		freq_err(sh, "%s: clock %u MHz: %d", c->name, o->mhz, ret);
		return ret;
	}
	if (want < uv) {
		ret = regulator_set_voltage(c->supply, want, want);
		if (ret != 0) {
			freq_err(sh, "%s: supply %u mV: %d", c->name, o->mv, ret);
			return ret;
		}
	}
	return 0;
}

static const struct opp *opp_find(const struct cluster *c, uint32_t mhz)
{
	for (size_t i = 0; i < c->nopp; i++) {
		if (c->opp[i].mhz == mhz) {
			return &c->opp[i];
		}
	}
	return NULL;
}

#if defined(CONFIG_SETTINGS)
#define FREQ_KEY "cpufreq"

/* settings: cpufreq/<cluster> = MHz (uint16_t) */
static int freq_load_cb(const char *key, size_t len, settings_read_cb read_cb, void *cb_arg,
			void *param)
{
	uint16_t *mhz = param;

	for (size_t i = 0; i < ARRAY_SIZE(clusters); i++) {
		if (key != NULL && strcmp(key, clusters[i].name) == 0 && len == sizeof(mhz[i])) {
			(void)read_cb(cb_arg, &mhz[i], sizeof(mhz[i]));
		}
	}
	return 0;
}

static int freq_save(const struct shell *sh, const struct device *cru, bool clear)
{
	char key[24];
	int ret = 0;

	for (size_t i = 0; i < ARRAY_SIZE(clusters) && ret == 0; i++) {
		const struct cluster *c = &clusters[i];
		uint32_t hz = 0;
		uint16_t mhz;

		(void)snprintk(key, sizeof(key), FREQ_KEY "/%s", c->name);
		if (clear) {
			ret = settings_delete(key);
			continue;
		}
		(void)clock_control_get_rate(cru, (clock_control_subsys_t)(uintptr_t)c->clk, &hz);
		mhz = (uint16_t)(hz / 1000000U);
		if (opp_find(c, mhz) == NULL) {
			shell_error(sh, "%s: %u MHz is not an operating point", c->name, mhz);
			return -EINVAL;
		}
		ret = settings_save_one(key, &mhz, sizeof(mhz));
		if (ret == 0) {
			shell_print(sh, "%s %u MHz from the next boot", c->name, mhz);
		}
	}
	if (ret != 0) {
		shell_error(sh, "settings: %d", ret);
	} else if (clear) {
		shell_print(sh, "boot loader clocks from the next boot");
	}
	return ret;
}

#define CRU_BASE           0xff760000UL
#define CRU_GLB_RST_ST     0x514U
#define GLB_RST_ST_WDT_MSK (BIT(4) | BIT(5))

/*
 * APPLICATION level: after the regulators (POST_KERNEL) and the eMMC
 * settings storage, before the secondary CPUs start (SMP level). After a
 * watchdog reset the saved points are skipped, in case they hung the board.
 */
static int freq_restore(void)
{
	const struct device *cru = DEVICE_DT_GET(DT_NODELABEL(cru_clk));
	uint16_t mhz[ARRAY_SIZE(clusters)] = {0};
	mm_reg_t rst;

	if (settings_subsys_init() != 0 ||
	    settings_load_subtree_direct(FREQ_KEY, freq_load_cb, mhz) != 0) {
		return 0;
	}
	device_map(&rst, CRU_BASE, 0x1000, K_MEM_CACHE_NONE);
	for (size_t i = 0; i < ARRAY_SIZE(clusters); i++) {
		const struct opp *o = opp_find(&clusters[i], mhz[i]);

		if (mhz[i] == 0U) {
			continue;
		}
		if ((sys_read32(rst + CRU_GLB_RST_ST) & GLB_RST_ST_WDT_MSK) != 0U) {
			printk("cpu freq: watchdog reset, saved %s %u MHz not applied\n",
			       clusters[i].name, mhz[i]);
		} else if (o == NULL) {
			printk("cpu freq: saved %s %u MHz is not an operating point\n",
			       clusters[i].name, mhz[i]);
		} else if (freq_set(NULL, cru, &clusters[i], o) == 0) {
			printk("cpu freq: %s %u MHz at %u mV (saved)\n", clusters[i].name, o->mhz,
			       o->mv);
		}
	}
	return 0;
}

SYS_INIT(freq_restore, APPLICATION, 0);
#endif

static int cmd_cpu_freq(const struct shell *sh, size_t argc, char **argv)
{
	const struct device *cru = DEVICE_DT_GET(DT_NODELABEL(cru_clk));
	const struct cluster *c = NULL;
	uint32_t mhz;
	char *end;
	int ret;

	if (argc == 1) {
		for (size_t i = 0; i < ARRAY_SIZE(clusters); i++) {
			freq_show(sh, cru, &clusters[i]);
		}
		return 0;
	}
#if defined(CONFIG_SETTINGS)
	if (strcmp(argv[1], "save") == 0 || strcmp(argv[1], "clear") == 0) {
		return freq_save(sh, cru, strcmp(argv[1], "clear") == 0);
	}
#endif
	for (size_t i = 0; i < ARRAY_SIZE(clusters); i++) {
		if (strcmp(argv[1], clusters[i].name) == 0) {
			c = &clusters[i];
		}
	}
	if (c == NULL) {
		shell_error(sh, "cpu freq [little|big [MHz] | save | clear]");
		return -EINVAL;
	}
	if (argc == 2) {
		freq_show(sh, cru, c);
		return 0;
	}
	mhz = strtoul(argv[2], &end, 0);
	if (*end != '\0') {
		shell_error(sh, "MHz: %s", argv[2]);
		return -EINVAL;
	}
	if (opp_find(c, mhz) != NULL) {
		ret = freq_set(sh, cru, c, opp_find(c, mhz));
		if (ret == 0) {
			freq_show(sh, cru, c);
		}
		return ret;
	}
	shell_error(sh, "%u MHz: not an operating point of the %s cluster:", mhz, c->name);
	for (size_t i = 0; i < c->nopp; i++) {
		shell_print(sh, "  %4u MHz at %u mV", c->opp[i].mhz, c->opp[i].mv);
	}
	return -EINVAL;
}
#endif

SHELL_STATIC_SUBCMD_SET_CREATE(sub_cpu,
	SHELL_CMD_ARG(info, NULL, "[cpu]: the same as cpu [cpu]", cmd_cpu_info, 1, 1),
	SHELL_CMD_ARG(irq, NULL,
		      "[ms] [cpu]: pending interrupt with IRQs masked, exception rate (all CPUs)",
		      cmd_cpu_irq, 1, 2),
#if DT_NODE_HAS_STATUS_OKAY(DT_NODELABEL(cru_clk))
	SHELL_CMD_ARG(freq, NULL, "[little|big [MHz] | save | clear]: core clocks and supplies",
		      cmd_cpu_freq, 1, 2),
#endif
	SHELL_SUBCMD_SET_END);

SHELL_CMD_ARG_REGISTER(cpu, &sub_cpu,
		       "[cpu]: CPU registers, memory attributes, clock and memory speed", cmd_cpu,
		       1, 1);
```

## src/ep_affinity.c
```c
/*
 * SPDX-FileCopyrightText: Copyright The Zephyr Project Contributors
 * SPDX-License-Identifier: Apache-2.0
 *
 * With SMP the endpoint gets a CPU of its own: its interrupts are routed
 * to the CPU the test function's command work queue is pinned to, and the
 * threads that exist at boot (shell, network, logging, main) may no longer
 * run there. Threads created later are not restricted.
 */

#include <zephyr/devicetree.h>
#include <zephyr/init.h>
#include <zephyr/kernel.h>
#include <zephyr/sys/printk.h>

#if defined(CONFIG_SMP) && defined(CONFIG_PCIE_EPF_TEST_CPU) && CONFIG_PCIE_EPF_TEST_CPU >= 0 &&  \
	DT_NODE_HAS_STATUS_OKAY(DT_NODELABEL(pcie0_ep))
#include <zephyr/drivers/interrupt_controller/gic.h>

#define EP_NODE DT_NODELABEL(pcie0_ep)

static K_THREAD_STACK_DEFINE(mpidr_stack, 1024);
static struct k_thread mpidr_thread;
static volatile uint64_t ep_mpidr;
static unsigned int ep_moved, ep_busy;

/* everything but the idle threads and the threads pinned to the EP CPU */
static void ep_cpu_release(const struct k_thread *t, void *user_data)
{
	struct k_thread *th = (struct k_thread *)t;
	uint32_t cpu = BIT(CONFIG_PCIE_EPF_TEST_CPU);
	bool *retry = user_data;

	if (th == k_current_get() || th->base.prio == K_IDLE_PRIO ||
	    (th->base.cpu_mask & cpu) == 0U || th->base.cpu_mask == cpu) {
		return;
	}
	/* only a thread that cannot run right now may change its mask */
	if (k_thread_cpu_mask_disable(th, CONFIG_PCIE_EPF_TEST_CPU) == 0) {
		ep_moved++;
	} else {
		*retry = true;
	}
}

/*
 * Runs on the EP CPU while the init thread (later main) waits for it in
 * k_thread_join(), so that one cannot run either and gets restricted too.
 */
static void mpidr_read(void *p1, void *p2, void *p3)
{
	ARG_UNUSED(p1);
	ARG_UNUSED(p2);
	ARG_UNUSED(p3);

	ep_mpidr = MPIDR_TO_CORE(GET_MPIDR());

	for (int pass = 0; pass < 10; pass++) {
		bool retry = false;

		k_thread_foreach_unlocked(ep_cpu_release, &retry);
		if (!retry) {
			ep_busy = 0U;
			return;
		}
		ep_busy = 1U;
		k_msleep(1);
	}
}

/*
 * The endpoint's interrupts (link events, uDMA done) go to the CPU of the
 * test function's work queue, so a transfer completes where it was started
 * and nothing on the other CPUs delays it. The MPIDR is read on that CPU,
 * so this runs at the SMP level, after the secondary CPUs are started.
 */
static int ep_irq_affinity(void)
{
	k_thread_create(&mpidr_thread, mpidr_stack, K_THREAD_STACK_SIZEOF(mpidr_stack), mpidr_read,
			NULL, NULL, NULL, K_PRIO_COOP(0), 0, K_FOREVER);
	k_thread_cpu_pin(&mpidr_thread, CONFIG_PCIE_EPF_TEST_CPU);
	k_thread_start(&mpidr_thread);
	if (k_thread_join(&mpidr_thread, K_SECONDS(1)) != 0) {
		printk("CPU%d did not run, PCIe endpoint interrupts stay on CPU0\n",
		       CONFIG_PCIE_EPF_TEST_CPU);
		k_thread_abort(&mpidr_thread);
		return 0;
	}

	arm_gic_irq_set_affinity(DT_IRQ_BY_NAME(EP_NODE, sys, irq), ep_mpidr);
	arm_gic_irq_set_affinity(DT_IRQ_BY_NAME(EP_NODE, legacy, irq), ep_mpidr);
	arm_gic_irq_set_affinity(DT_IRQ_BY_NAME(EP_NODE, client, irq), ep_mpidr);
	printk("PCIe endpoint interrupts on CPU%d (MPIDR 0x%llx), %u threads moved off it%s\n",
	       CONFIG_PCIE_EPF_TEST_CPU, (unsigned long long)ep_mpidr, ep_moved,
	       ep_busy != 0U ? ", some still allowed (they kept running)" : "");
	return 0;
}

SYS_INIT(ep_irq_affinity, SMP, 0);
#endif
```

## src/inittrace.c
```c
/*
 * Copyright (c) 2026 Jiri Kastner
 * SPDX-License-Identifier: Apache-2.0
 *
 * Markers between init priorities (CONFIG_SAMPLE_INIT_TRACE): the last
 * one printed brackets the device whose init does not return.
 * RK3399 drivers here: reset 35, GPIO 40, syscon 50, SDHC 70 (eMMC, SD),
 * SPI/SPI NOR 70/80, eMMC mount 76, role 81, EPC 82, EPF 83, RC 84.
 */

#include <zephyr/init.h>
#include <zephyr/sys/printk.h>
#include <zephyr/arch/cpu.h>
#include <zephyr/sys/sys_io.h>

/*
 * With CONFIG_RK3399_EARLY_MARKS the marker also goes straight to UART2
 * (identity mapped then), so it shows even when printk output is held back
 * (shell log backend not started yet) or the console driver misbehaves.
 */
static void raw(const char *s)
{
#if defined(CONFIG_RK3399_EARLY_MARKS)
	for (; *s != '\0'; s++) {
		while ((sys_read32(0xff1a0014UL) & 0x20U) == 0U) {
		}
		sys_write32((uint32_t)*s, 0xff1a0000UL);
	}
#else
	ARG_UNUSED(s);
#endif
}

#define MARK(level, prio)                                                                          \
	static int mark_##level##_##prio(void)                                                     \
	{                                                                                          \
		raw("\r\n[raw] init: " #level " " #prio "\r\n");                                    \
		printk("init: " #level " " #prio "\n");                                            \
		return 0;                                                                          \
	}                                                                                          \
	SYS_INIT(mark_##level##_##prio, level, prio)

MARK(PRE_KERNEL_2, 0);
MARK(POST_KERNEL, 0);
MARK(POST_KERNEL, 36);
MARK(POST_KERNEL, 41);
MARK(POST_KERNEL, 51);
MARK(POST_KERNEL, 69);
MARK(POST_KERNEL, 71);
MARK(POST_KERNEL, 75);
MARK(POST_KERNEL, 77);
MARK(POST_KERNEL, 80);
MARK(POST_KERNEL, 82);
MARK(POST_KERNEL, 83);
MARK(POST_KERNEL, 84);
MARK(POST_KERNEL, 85);
MARK(POST_KERNEL, 99);
MARK(APPLICATION, 0);
```
